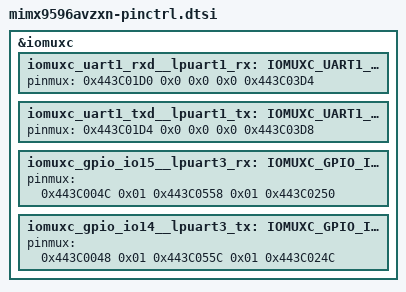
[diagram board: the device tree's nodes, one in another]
/*
 * Copyright (c) 2022, NXP
 * SPDX-License-Identifier: Apache-2.0
 *
 * Note: File generated by imx_cfg_utils.py
 * from configuration data for MIMX8ML8DVNLZ
 */

/*
 * SOC level pinctrl defintions
 * These definitions define SOC level defaults for each pin,
 * and select the pinmux for the pin. Pinmux entries are a tuple of:
 * <mux_register mux_mode input_register input_daisy config_register>
 * the mux_register and input_daisy reside in the IOMUXC peripheral, and
 * the pinctrl driver will write the mux_mode and input_daisy values into
 * each register, respectively. The config_register is used to configure
 * the pin based on the devicetree properties set
 */

&iomuxc {
	/omit-if-no-ref/ iomuxc_uart1_rxd__lpuart1_rx: IOMUXC_UART1_RXD__LPUART1_RX {
		pinmux = <0x443C01D0 0x0 0x0 0x0 0x443C03D4>;
	};
	/omit-if-no-ref/ iomuxc_uart1_txd__lpuart1_tx: IOMUXC_UART1_TXD__LPUART1_TX {
		pinmux = <0x443C01D4 0x0 0x0 0x0 0x443C03D8>;
	};

	/omit-if-no-ref/ iomuxc_gpio_io15__lpuart3_rx: IOMUXC_GPIO_IO15__LPUART3_RX {
		pinmux = <0x443C004C 0x01 0x443C0558 0x01 0x443C0250>;
	};
	/omit-if-no-ref/ iomuxc_gpio_io14__lpuart3_tx: IOMUXC_GPIO_IO14__LPUART3_TX {
		pinmux = <0x443C0048 0x01 0x443C055C 0x01 0x443C024C>;
	};
};

